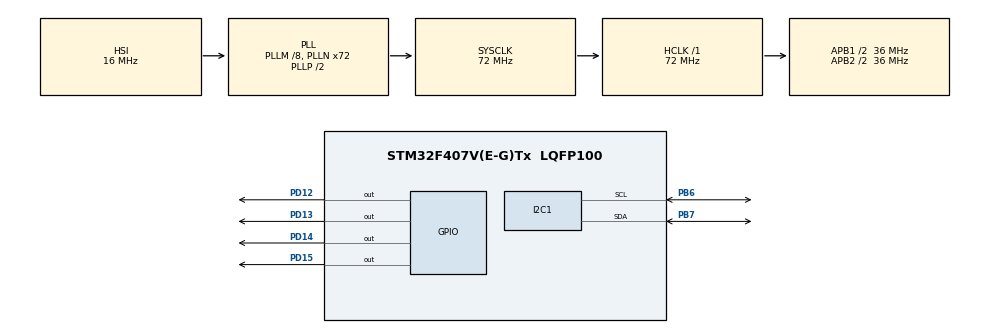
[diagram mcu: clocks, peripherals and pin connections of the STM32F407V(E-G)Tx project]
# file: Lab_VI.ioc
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Mcu.Family=STM32F4
Mcu.Name=STM32F407V(E-G)Tx
Mcu.Package=LQFP100
NVIC.I2C1_ER_IRQn=true\:0\:0\:false\:false\:true\:true\:true\:true
NVIC.I2C1_EV_IRQn=true\:0\:0\:false\:false\:true\:true\:true\:true
NVIC.PriorityGroup=NVIC_PRIORITYGROUP_0
PA13.Mode=Trace_Asynchronous_SW
PA13.Signal=SYS_JTMS-SWDIO
PA14.Mode=Trace_Asynchronous_SW
PA14.Signal=SYS_JTCK-SWCLK
PB3.Mode=Trace_Asynchronous_SW
PB3.Signal=SYS_JTDO-SWO
PB6.GPIO_Pu=GPIO_PULLUP
PB6.Mode=I2C
PB6.Signal=I2C1_SCL
PB7.GPIO_Pu=GPIO_PULLUP
PB7.Mode=I2C
PB7.Signal=I2C1_SDA
PD12.Signal=GPIO_Output
PD13.Signal=GPIO_Output
PD14.Signal=GPIO_Output
PD15.Signal=GPIO_Output
ProjectManager.HeapSize=0x200
ProjectManager.StackSize=0x400
ProjectManager.TargetToolchain=STM32CubeIDE
RCC.48MHZClocksFreq_Value=20571428.57142857
RCC.AHBFreq_Value=72000000
RCC.APB1CLKDivider=RCC_HCLK_DIV2
RCC.APB1Freq_Value=36000000
RCC.APB1TimFreq_Value=72000000
RCC.APB2CLKDivider=RCC_HCLK_DIV2
RCC.APB2Freq_Value=36000000
RCC.APB2TimFreq_Value=72000000
RCC.CortexFreq_Value=72000000
RCC.HCLKFreq_Value=72000000
RCC.HSE_VALUE=8000000
RCC.HSI_VALUE=16000000
RCC.PLLM=8
RCC.PLLN=72
RCC.PLLQ=7
RCC.SYSCLKFreq_VALUE=72000000
RCC.SYSCLKSource=RCC_SYSCLKSOURCE_PLLCLK
RCC.VCOOutputFreq_Value=144000000
board=STM32F407G-DISC1

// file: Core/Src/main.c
/* USER CODE BEGIN Header */
/**
  ******************************************************************************
  * @file           : main.c
  * @brief          : Main program body
  ******************************************************************************
  * @attention
  *
  * Copyright (c) 2023 STMicroelectronics.
  * All rights reserved.
  *
  * This software is licensed under terms that can be found in the LICENSE file
  * in the root directory of this software component.
  * If no LICENSE file comes with this software, it is provided AS-IS.
  *
  ******************************************************************************
  */
/* USER CODE END Header */
#include "main.h"

/* USER CODE BEGIN PD */
#define I2C_ADDRESS         0xFA
/* USER CODE END PD */

I2C_HandleTypeDef hi2c1;

int i = 0;
uint8_t aTx = 0x05;
uint8_t aRx = 0;
uint8_t aTxBuffer[3] = {0x01, 0x05, 0x0F};

void SystemClock_Config(void);
static void MX_GPIO_Init(void);
static void MX_I2C1_Init(void);

int main(void)
{

  /* MCU Configuration--------------------------------------------------------*/

  /* Reset of all peripherals, Initializes the Flash interface and the Systick. */
  HAL_Init();

  /* Configure the system clock */
  SystemClock_Config();

  /* Initialize all configured peripherals */
  MX_GPIO_Init();
  MX_I2C1_Init();

  /* Infinite loop */
  /* USER CODE BEGIN WHILE */
  while (1)
  {
	    if(HAL_I2C_IsDeviceReady(&hi2c1, I2C_ADDRESS, 1, 10) == HAL_OK)
	    {
	      HAL_GPIO_WritePin(GPIOD, GPIO_PIN_15, GPIO_PIN_SET);
	      HAL_GPIO_WritePin(GPIOD, GPIO_PIN_12, GPIO_PIN_RESET);
	      HAL_I2C_Master_Transmit(&hi2c1, I2C_ADDRESS, &aTxBuffer[i], 1, 10);
	    }
	    else
	    {
	      HAL_GPIO_WritePin(GPIOD, GPIO_PIN_12, GPIO_PIN_SET);
	      HAL_GPIO_WritePin(GPIOD, GPIO_PIN_15, GPIO_PIN_RESET);
	    }

	    if (i < 2)
	    {
	      i = i + 1;
	    }
	    else
	    {
	      i = 0;
	    }
    /* USER CODE END WHILE */

  }
}

void SystemClock_Config(void)
{
  RCC_OscInitTypeDef RCC_OscInitStruct = {0};
  RCC_ClkInitTypeDef RCC_ClkInitStruct = {0};

  /** Configure the main internal regulator output voltage
  */
  __HAL_RCC_PWR_CLK_ENABLE();
  __HAL_PWR_VOLTAGESCALING_CONFIG(PWR_REGULATOR_VOLTAGE_SCALE1);

  /** Initializes the RCC Oscillators according to the specified parameters
  * in the RCC_OscInitTypeDef structure.
  */
  RCC_OscInitStruct.OscillatorType = RCC_OSCILLATORTYPE_HSI;
  RCC_OscInitStruct.HSIState = RCC_HSI_ON;
  RCC_OscInitStruct.HSICalibrationValue = RCC_HSICALIBRATION_DEFAULT;
  RCC_OscInitStruct.PLL.PLLState = RCC_PLL_ON;
  RCC_OscInitStruct.PLL.PLLSource = RCC_PLLSOURCE_HSI;
  RCC_OscInitStruct.PLL.PLLM = 8;
  RCC_OscInitStruct.PLL.PLLN = 72;
  RCC_OscInitStruct.PLL.PLLP = RCC_PLLP_DIV2;
  RCC_OscInitStruct.PLL.PLLQ = 7;
  if (HAL_RCC_OscConfig(&RCC_OscInitStruct) != HAL_OK)
  {
    Error_Handler();
  }

  /** Initializes the CPU, AHB and APB buses clocks
  */
  RCC_ClkInitStruct.ClockType = RCC_CLOCKTYPE_HCLK|RCC_CLOCKTYPE_SYSCLK
                              |RCC_CLOCKTYPE_PCLK1|RCC_CLOCKTYPE_PCLK2;
  RCC_ClkInitStruct.SYSCLKSource = RCC_SYSCLKSOURCE_PLLCLK;
  RCC_ClkInitStruct.AHBCLKDivider = RCC_SYSCLK_DIV1;
  RCC_ClkInitStruct.APB1CLKDivider = RCC_HCLK_DIV2;
  RCC_ClkInitStruct.APB2CLKDivider = RCC_HCLK_DIV2;

  if (HAL_RCC_ClockConfig(&RCC_ClkInitStruct, FLASH_LATENCY_2) != HAL_OK)
  {
    Error_Handler();
  }
}

static void MX_I2C1_Init(void)
{

  hi2c1.Instance = I2C1;
  hi2c1.Init.ClockSpeed = 100000;
  hi2c1.Init.DutyCycle = I2C_DUTYCYCLE_2;
  hi2c1.Init.OwnAddress1 = 0;
  hi2c1.Init.AddressingMode = I2C_ADDRESSINGMODE_7BIT;
  hi2c1.Init.DualAddressMode = I2C_DUALADDRESS_DISABLE;
  hi2c1.Init.OwnAddress2 = 0;
  hi2c1.Init.GeneralCallMode = I2C_GENERALCALL_DISABLE;
  hi2c1.Init.NoStretchMode = I2C_NOSTRETCH_DISABLE;
  if (HAL_I2C_Init(&hi2c1) != HAL_OK)
  {
    Error_Handler();
  }

}

static void MX_GPIO_Init(void)
{
  GPIO_InitTypeDef GPIO_InitStruct = {0};

  /* GPIO Ports Clock Enable */
  __HAL_RCC_GPIOD_CLK_ENABLE();
  __HAL_RCC_GPIOA_CLK_ENABLE();
  __HAL_RCC_GPIOB_CLK_ENABLE();

  /*Configure GPIO pin Output Level */
  HAL_GPIO_WritePin(GPIOD, GPIO_PIN_12|GPIO_PIN_13|GPIO_PIN_14|GPIO_PIN_15, GPIO_PIN_RESET);

  /*Configure GPIO pins : PD12 PD13 PD14 PD15 */
  GPIO_InitStruct.Pin = GPIO_PIN_12|GPIO_PIN_13|GPIO_PIN_14|GPIO_PIN_15;
  GPIO_InitStruct.Mode = GPIO_MODE_OUTPUT_PP;
  GPIO_InitStruct.Pull = GPIO_NOPULL;
  GPIO_InitStruct.Speed = GPIO_SPEED_FREQ_LOW;
  HAL_GPIO_Init(GPIOD, &GPIO_InitStruct);

}

void Error_Handler(void)
{
  __disable_irq();
  while (1)
  {
  }
}
